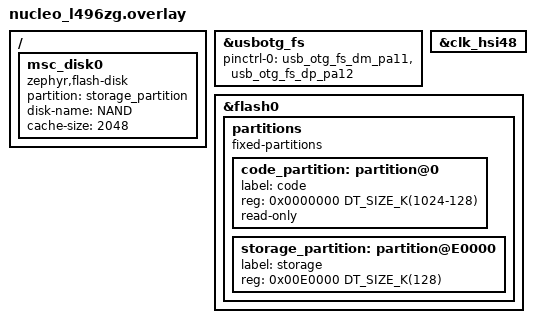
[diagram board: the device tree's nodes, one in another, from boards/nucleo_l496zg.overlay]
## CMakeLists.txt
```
# Copyright (c) 2024 Schneider Electric
# SPDX-License-Identifier: Apache-2.0

cmake_minimum_required(VERSION 3.20.0)

find_package(Zephyr REQUIRED HINTS $ENV{ZEPHYR_BASE})

project(fs_loader)

target_sources(app PRIVATE src/main.c src/log_extension.c src/export.c)

# declare extension
zephyr_llext(hello_world)
zephyr_llext_sources(hello_world.llext/hello_world.c)

zephyr_llext(hello_world_pic PIC)
zephyr_llext_sources(hello_world.llext/hello_world.c)

set(FAT_IMG ${CMAKE_CURRENT_BINARY_DIR}/llext_vfat.img)

# generate image
add_custom_target(vfat.img ALL
    COMMAND ${CMAKE_CURRENT_LIST_DIR}/makeimg.sh ${FAT_IMG} ${CMAKE_CURRENT_BINARY_DIR}/hello_world.llext ${CMAKE_CURRENT_BINARY_DIR}/hello_world_pic.llext
    WORKING_DIRECTORY ${ZEPHYR_BASE}
    SOURCES ${CMAKE_CURRENT_LIST_DIR}/makeimg.sh
    DEPENDS ${CMAKE_CURRENT_BINARY_DIR}/hello_world.llext ${CMAKE_CURRENT_BINARY_DIR}/hello_world_pic.llext
)
```

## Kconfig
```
#
# Copyright (c) 2024 Schneider Electric
#
# SPDX-License-Identifier: Apache-2.0
#

config APP_WIPE_STORAGE
	bool "Option to clear the flash area before mounting"
	help
	  Use this to force an existing file system to be created.

config CONFIG_LLEXT_PIC
	bool "Build LL extension with PIC enabled"
	help
	  Use this to force building LL extension in Position Independant Code.

source "Kconfig.zephyr"
```

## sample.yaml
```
sample:
  description: Loadable extensions with filesystem sample
  name: Extension loader filesystem
tests:
  sample.llext.filesystem:
    tags: llext
    harness: keyboard
    arch_allow: arm
    depends_on:
      - usb_device
      - filesystem
```

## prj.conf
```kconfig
# heap size
CONFIG_HEAP_MEM_POOL_SIZE=2048
CONFIG_SYS_HEAP_RUNTIME_STATS=y

# log config
CONFIG_LOG=y
CONFIG_LOG_BUFFER_SIZE=512
CONFIG_LOG_BLOCK_IN_THREAD=y
CONFIG_LOG_BLOCK_IN_THREAD_TIMEOUT_MS=1000
CONFIG_LOG_PROCESS_THREAD_SLEEP_MS=10
CONFIG_LOG_PROCESS_THREAD_CUSTOM_PRIORITY=y
CONFIG_LOG_PROCESS_THREAD_PRIORITY=10

CONFIG_GPIO=y


# Optionally force the file system to be recreated
#CONFIG_APP_WIPE_STORAGE=y
CONFIG_FLASH=y
CONFIG_FLASHDISK_LOG_LEVEL_WRN=y
CONFIG_FILE_SYSTEM=y
CONFIG_FILE_SYSTEM_SHELL=y
CONFIG_DISK_ACCESS=y
CONFIG_DISK_DRIVERS=y
CONFIG_DISK_DRIVER_FLASH=y
CONFIG_FAT_FILESYSTEM_ELM=y
CONFIG_FS_FATFS_LFN=y

CONFIG_FLASH_MAP=y
CONFIG_FLASH_PAGE_LAYOUT=y
CONFIG_FLASH_MAP_SHELL=y
CONFIG_FS_LOG_LEVEL_WRN=y

# main stack size
CONFIG_MAIN_STACK_SIZE=2048


CONFIG_REBOOT=y

#shell
CONFIG_SHELL=y
CONFIG_SHELL_CMD_BUFF_SIZE=512
CONFIG_SHELL_LOG_LEVEL_INF=y
CONFIG_SHELL_STACK_SIZE=2048


#USB related configs
CONFIG_USB_DEVICE_STACK=y
CONFIG_USB_DEVICE_PRODUCT="Zephyr"
CONFIG_USB_DEVICE_PID=0x0008
CONFIG_USB_DRIVER_LOG_LEVEL_ERR=y
CONFIG_USB_MASS_STORAGE=y
CONFIG_MASS_STORAGE_DISK_NAME="NAND"
CONFIG_USB_DEVICE_LOG_LEVEL_ERR=y
CONFIG_USB_MASS_STORAGE_LOG_LEVEL_ERR=y
CONFIG_USB_DEVICE_INITIALIZE_AT_BOOT=n


CONFIG_LLEXT=y
CONFIG_LLEXT_LOG_LEVEL_INF=y
 # LLEXT heap size in Kilobytes
CONFIG_LLEXT_HEAP_SIZE=32
CONFIG_LLEXT_SHELL=y
CONFIG_LLEXT_HEAP_STAT=y
```

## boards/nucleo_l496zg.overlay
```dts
/*
 * Copyright (c) 2024 Schneider Electric
 *
 * SPDX-License-Identifier: Apache-2.0
 */

&usbotg_fs {
    pinctrl-0 = <&usb_otg_fs_dm_pa11 &usb_otg_fs_dp_pa12>;
	pinctrl-names = "default";
	status = "okay";
};
/* hsi48 must be enabled for usb */
&clk_hsi48 {
	status = "okay";
};

&flash0 {
	partitions {
		compatible = "fixed-partitions";
		#address-cells = <1>;
		#size-cells = <1>;

		code_partition: partition@0 {
			label = "code";
			reg = <0x0000000 DT_SIZE_K(1024-128)>;
			read-only;
		};

		/*
		 * The final 128 KiB is reserved for the application.
		 * Storage partition will be used by FCB/LittleFS/NVS
		 * if enabled.
		 */
		storage_partition: partition@E0000 {
			label = "storage";
			reg = <0x00E0000 DT_SIZE_K(128)>;
		};
	};
};

/ {
	msc_disk0 {
		status="okay";
		compatible = "zephyr,flash-disk";
		partition = <&storage_partition>;
		disk-name = "NAND";
		/* cache-size == page erase size */
		cache-size = <2048>;
	};
};
```

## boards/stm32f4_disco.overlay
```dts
/*
 * Copyright (c) 2024 Schneider Electric
 *
 * SPDX-License-Identifier: Apache-2.0
 */

&flash0 {
	partitions {
		compatible = "fixed-partitions";
		#address-cells = <1>;
		#size-cells = <1>;

		code_partition: partition@0 {
			label = "code";
			reg = <0x0000000 DT_SIZE_K(1024-128)>;
			read-only;
		};

		/*
		 * The final 128 KiB is reserved for the application.
		 * Storage partition will be used by FCB/LittleFS/NVS
		 * if enabled.
		 */
		storage_partition: partition@E0000 {
			label = "storage";
			reg = <0x00E0000 DT_SIZE_K(128)>;
			read-only;
		};
	};
};

/ {
	msc_disk0 {
		status="okay";
		compatible = "zephyr,flash-disk";
		partition = <&storage_partition>;
		disk-name = "NAND";
		/* cache-size == page erase size */
		cache-size = <2048>;
	};
};
```

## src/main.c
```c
/*
 * Copyright (c) 2024 Schneider Electric
 *
 * SPDX-License-Identifier: Apache-2.0
 */

#include <zephyr/kernel.h>
#include <zephyr/drivers/gpio.h>
#include <zephyr/sys/reboot.h>
#include <zephyr/settings/settings.h>
#if CONFIG_USB_DEVICE_STACK
#include <zephyr/usb/usb_device.h>
#include <zephyr/usb/usbd.h>
#include <zephyr/usb/class/usbd_msc.h>
#endif
#include <zephyr/fs/fs.h>
#include <app_version.h>
#if CONFIG_LLEXT
#include <zephyr/llext/llext.h>
#include <zephyr/llext/buf_loader.h>
#include <zephyr/llext/file_loader.h>
#endif


#define LOG_LEVEL LOG_LEVEL_DBG
#include <zephyr/logging/log.h>
LOG_MODULE_REGISTER(app);


#if CONFIG_DISK_DRIVER_FLASH
#include <zephyr/storage/flash_map.h>
#endif

#if CONFIG_FAT_FILESYSTEM_ELM
#include <ff.h>
#endif

#if CONFIG_FILE_SYSTEM_LITTLEFS
#include <zephyr/fs/littlefs.h>
FS_LITTLEFS_DECLARE_DEFAULT_CONFIG(storage);
#endif


#define CAN_INTERFACE    DEVICE_DT_GET(DT_CHOSEN(zephyr_canbus))
#define CAN_BITRATE    (DT_PROP(DT_CHOSEN(zephyr_canbus), bus_speed) / 1000)


#define STORAGE_PARTITION       storage_partition
#define STORAGE_PARTITION_ID    FIXED_PARTITION_ID(STORAGE_PARTITION)


static struct fs_mount_t fs_mnt;

static int setup_flash(struct fs_mount_t *mnt)
{
	int rc = 0;
#if CONFIG_DISK_DRIVER_FLASH
	unsigned int id;
	const struct flash_area *pfa;

	mnt->storage_dev = (void *)STORAGE_PARTITION_ID;
	id = STORAGE_PARTITION_ID;

	rc = flash_area_open(id, &pfa);
	printk("Area %u at 0x%x on %s for %u bytes\n",
		   id, (unsigned int)pfa->fa_off, pfa->fa_dev->name,
		   (unsigned int)pfa->fa_size);

	if (rc < 0 && IS_ENABLED(CONFIG_APP_WIPE_STORAGE)) {
		printk("Erasing flash area ... ");
		rc = flash_area_erase(pfa, 0, pfa->fa_size);
		printk("%d\n", rc);
	}

	if (rc < 0) {
		flash_area_close(pfa);
	}
#endif
	return rc;
}

static int mount_app_fs(struct fs_mount_t *mnt)
{
	int rc;

#if CONFIG_FAT_FILESYSTEM_ELM
	static FATFS fat_fs;

	mnt->type = FS_FATFS;
	mnt->fs_data = &fat_fs;
	if (IS_ENABLED(CONFIG_DISK_DRIVER_RAM)) {
		mnt->mnt_point = "/RAM:";
	} else if (IS_ENABLED(CONFIG_DISK_DRIVER_SDMMC)) {
		mnt->mnt_point = "/SD:";
	} else {
		mnt->mnt_point = "/NAND:";
	}

#elif CONFIG_FILE_SYSTEM_LITTLEFS
	mnt->type = FS_LITTLEFS;
	mnt->mnt_point = "/lfs";
	mnt->fs_data = &storage;
#endif
	rc = fs_mount(mnt);

	return rc;
}

static void setup_disk(void)
{
	struct fs_mount_t *mp = &fs_mnt;
	struct fs_dir_t dir;
	struct fs_statvfs sbuf;
	int rc;

	fs_dir_t_init(&dir);

	if (IS_ENABLED(CONFIG_DISK_DRIVER_FLASH)) {
		rc = setup_flash(mp);
		if (rc < 0) {
			LOG_ERR("Failed to setup flash area");
			return;
		}
	}

	if (!IS_ENABLED(CONFIG_FILE_SYSTEM_LITTLEFS) &&
		!IS_ENABLED(CONFIG_FAT_FILESYSTEM_ELM)) {
		LOG_INF("No file system selected");
		return;
	}

	rc = mount_app_fs(mp);
	if (rc < 0) {
		LOG_ERR("Failed to mount filesystem");
		return;
	}

	/* Allow log messages to flush to avoid interleaved output */
	k_sleep(K_MSEC(50));

	printk("Mount %s: %d\n", fs_mnt.mnt_point, rc);

	rc = fs_statvfs(mp->mnt_point, &sbuf);
	if (rc < 0) {
		printk("FAIL: statvfs: %d\n", rc);
		return;
	}

	printk("%s: bsize = %lu ; frsize = %lu ;"
		   " blocks = %lu ; bfree = %lu\n",
		   mp->mnt_point,
		   sbuf.f_bsize, sbuf.f_frsize,
		   sbuf.f_blocks, sbuf.f_bfree);

	rc = fs_opendir(&dir, mp->mnt_point);
	printk("%s opendir: %d\n", mp->mnt_point, rc);

	if (rc < 0) {
		LOG_ERR("Failed to open directory");
	}

	while (rc >= 0) {
		struct fs_dirent ent = { 0 };

		rc = fs_readdir(&dir, &ent);
		if (rc < 0) {
			LOG_ERR("Failed to read directory entries");
			break;
		}
		if (ent.name[0] == 0) {
			printk("End of files\n");
			break;
		}
		printk("  %c %u %s\n",
			   (ent.type == FS_DIR_ENTRY_FILE) ? 'F' : 'D',
			   ent.size,
			   ent.name);
	}

	(void)fs_closedir(&dir);
}

/**
 * find all elf file and load it
 */
void load_extension(void)
{
	struct fs_file_t fd;
	char extension_names[2][16] = {"hello_world","hello_world_pic"};
	char extension_paths[2][64] = {"/NAND:/hello_world.llext","/NAND:/hello_world_pic.llext"};

	for (int i=0; i<2; i++) {
		char * extension_name = extension_names[i];
		char * extension_path = extension_paths[i];
		LOG_INF("Loading extension %s %s", extension_name, extension_path);

		fs_file_t_init(&fd);
		int rc = fs_open(&fd, extension_path, FS_O_READ);
		if(rc < 0) {
			LOG_ERR("%d extension not found: %s", rc, extension_path);
		} else {
			struct llext_load_param ldr_parm = LLEXT_LOAD_PARAM_DEFAULT;
			struct llext_file_loader file_stream = LLEXT_FILE_LOADER(&fd);
			struct llext_loader *stream = &file_stream.loader;

			struct llext *m;
			int res = llext_load(stream, extension_name, &m, &ldr_parm);

			fs_close(&fd);

			if (res == 0) {

				LOG_INF("Successfully loaded extension %s @ %p", m->name, m->mem[LLEXT_MEM_TEXT]);
				// start extension
				LOG_INF("Starting extension %s", m->name);
				int rc = llext_call_fn(m, "start");
				if(rc != 0)
				{
					LOG_ERR("Failed to start extension %s", m->name);
				}
			} else {
				LOG_ERR("Failed to load extension %s, return code %d", extension_name, res);
			}
		}
	}
}



/**
 * @brief Main application entry point.
 *
 */
int main(void)
{
	int ret;

	printf("\n\t\t\x1B[36m====== LLEXT fs_loader sample %s ======\x1B[0m", APP_VERSION_STRING);

	setup_disk();

#if defined(CONFIG_USB_DEVICE_STACK_NEXT)
	ret = enable_usb_device_next();
#else
	ret = usb_enable(NULL);
#endif
	if (ret != 0) {
		LOG_ERR("Failed to enable USB");
		return 0;
	}
#if defined(CONFIG_USB_MASS_STORAGE)
	LOG_INF("The device is put in USB mass storage mode.");
#endif

	LOG_INF("End of boot");

#ifdef CONFIG_LLEXT
	LOG_INF("Start extension loading");
	load_extension();
	LOG_INF("End of extension loading");
#endif

	return 0;
}
```

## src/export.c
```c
/*
 * Copyright (c) 2024 Schneider Electric
 *
 * SPDX-License-Identifier: Apache-2.0
 */


#include <zephyr/device.h>
#include <zephyr/drivers/can.h>
#include <zephyr/kernel.h>
#include <zephyr/logging/log.h>
#include <zephyr/sys/crc.h>
#include <zephyr/sys/mutex.h>
#include <zephyr/sys/printk.h>
#include <zephyr/sys/reboot.h>
#include <zephyr/llext/symbol.h>



/* export symbol kernel */
EXPORT_SYMBOL(printk);
EXPORT_SYMBOL(sys_clock_cycle_get_32);
EXPORT_SYSCALL(k_mutex_lock);
EXPORT_SYSCALL(k_mutex_unlock);
EXPORT_SYSCALL(k_sleep);
EXPORT_SYSCALL(k_thread_create);
EXPORT_SYSCALL(k_thread_name_set);
EXPORT_SYSCALL(k_timer_start);
EXPORT_SYSCALL(k_timer_stop);
EXPORT_SYSCALL(k_uptime_ticks);
EXPORT_SYSCALL(z_log_msg_static_create);
EXPORT_SYSCALL(z_log_msg_simple_create_0);
EXPORT_SYSCALL(z_log_msg_simple_create_1);
EXPORT_SYSCALL(z_log_msg_simple_create_2);
EXPORT_SYMBOL(z_timer_expiration_handler);
EXPORT_SYSCALL(k_sched_current_thread_query);
EXPORT_SYMBOL(k_object_access_revoke);
EXPORT_SYSCALL(k_sem_init);
EXPORT_SYSCALL(k_sem_take);
EXPORT_SYSCALL(k_sem_give);

#ifdef CONFIG_USERSPACE
EXPORT_SYMBOL(z_arm_thread_is_in_user_mode);
EXPORT_SYSCALL(k_object_access_grant);
EXPORT_SYMBOL(k_thread_user_mode_enter);
#ifdef CONFIG_DYNAMIC_THREAD
EXPORT_SYSCALL(k_thread_stack_alloc);
#endif
#ifdef CONFIG_DYNAMIC_OBJECTS
EXPORT_SYSCALL(k_object_alloc);
#endif
#endif

#ifdef CONFIG_TRACING_USER
EXPORT_SYMBOL(sys_trace_poc_log);
#endif

#ifdef CONFIG_SEGGER_SYSTEMVIEW
EXPORT_SYMBOL(SEGGER_SYSVIEW_RecordEndCall);
EXPORT_SYMBOL(SEGGER_SYSVIEW_RecordString);
EXPORT_SYMBOL(SEGGER_SYSVIEW_MarkStart);
EXPORT_SYMBOL(SEGGER_SYSVIEW_MarkStop);
EXPORT_SYMBOL(SEGGER_SYSVIEW_PrintfHost);
#endif
```

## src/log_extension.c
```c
/*
 * Copyright (c) 2024 Schneider Electric
 *
 * SPDX-License-Identifier: Apache-2.0
 */

#define LOG_LEVEL LOG_LEVEL_DBG
#include <zephyr/logging/log.h>
LOG_MODULE_REGISTER(extension, LOG_LEVEL);

#ifdef CONFIG_LLEXT
#include <zephyr/llext/symbol.h>
EXPORT_SYMBOL(log_dynamic_extension);
#endif
```
